VERSION "1.0"

NS_ :

BS_:

BU_: BMS TELEMATICS

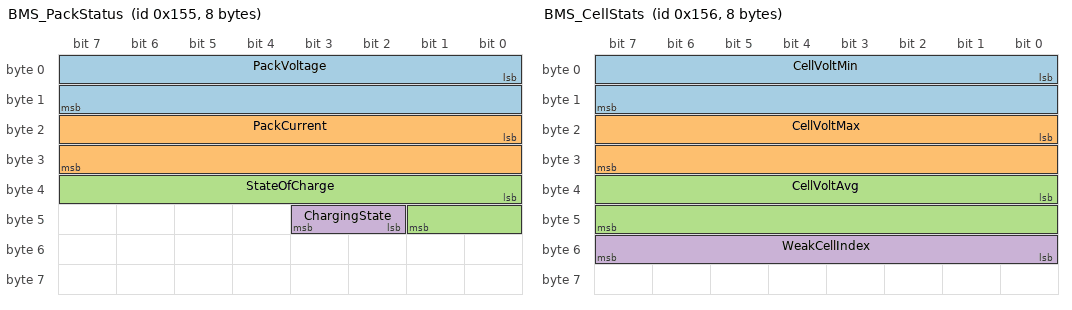
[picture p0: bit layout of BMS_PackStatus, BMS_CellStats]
BO_ 341 BMS_PackStatus: 8 BMS
 SG_ PackVoltage : 0|16@1+ (0.1,0) [0|800] "V"  TELEMATICS
 SG_ PackCurrent : 16|16@1- (0.1,0) [-3000|3000] "A"  TELEMATICS
 SG_ StateOfCharge : 32|10@1+ (0.1,0) [0|102.3] "%"  TELEMATICS
 SG_ ChargingState : 42|2@1+ (1,0) [0|3] ""  TELEMATICS

BO_ 342 BMS_CellStats: 8 BMS
 SG_ CellVoltMin : 0|16@1+ (1,0) [0|6000] "mV"  TELEMATICS
 SG_ CellVoltMax : 16|16@1+ (1,0) [0|6000] "mV"  TELEMATICS
 SG_ CellVoltAvg : 32|16@1+ (1,0) [0|6000] "mV"  TELEMATICS
 SG_ WeakCellIndex : 48|8@1+ (1,0) [0|255] ""  TELEMATICS

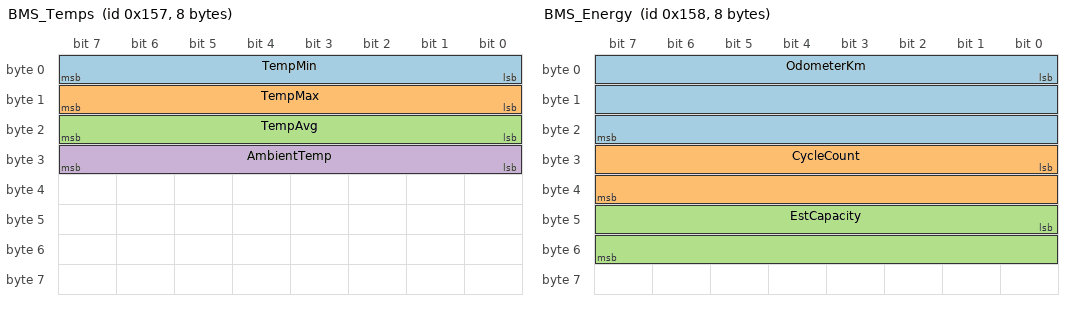
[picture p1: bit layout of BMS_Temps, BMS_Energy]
BO_ 343 BMS_Temps: 8 BMS
 SG_ TempMin : 0|8@1+ (1,-40) [-40|215] "degC"  TELEMATICS
 SG_ TempMax : 8|8@1+ (1,-40) [-40|215] "degC"  TELEMATICS
 SG_ TempAvg : 16|8@1+ (1,-40) [-40|215] "degC"  TELEMATICS
 SG_ AmbientTemp : 24|8@1+ (1,-40) [-40|215] "degC"  TELEMATICS

BO_ 344 BMS_Energy: 8 BMS
 SG_ OdometerKm : 0|24@1+ (1,0) [0|16777215] "km"  TELEMATICS
 SG_ CycleCount : 24|16@1+ (0.1,0) [0|6553.5] ""  TELEMATICS
 SG_ EstCapacity : 40|16@1+ (0.01,0) [0|655.35] "Ah"  TELEMATICS

CM_ BO_ 341 "Pack-level electrical status, 1 Hz";
CM_ BO_ 342 "Cell voltage statistics for imbalance monitoring";
CM_ BO_ 343 "Pack thermal statistics";
CM_ BO_ 344 "Lifetime energy counters and capacity estimate";
